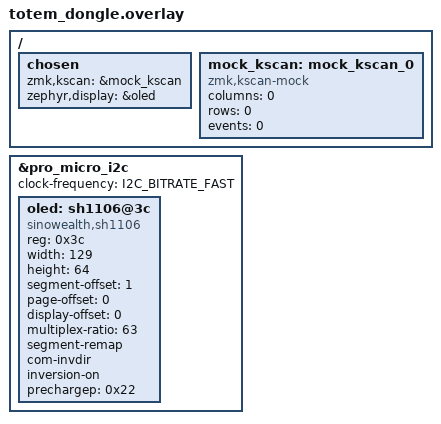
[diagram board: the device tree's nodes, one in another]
/* Import the logical layout and keymap for ZMK Studio */
#include <boards/shields/totem/totem.dtsi>

/ {
    chosen {
        zmk,kscan = &mock_kscan;
        zephyr,display = &oled;
    };

    /* Provide a dummy scanner so the nice!nano doesn't panic looking for keys */
    mock_kscan: mock_kscan_0 {
        compatible = "zmk,kscan-mock";
        columns = <0>;
        rows = <0>;
        events = <0>;
    };
};

/* Use the native nice!nano pins for the I2C OLED */
&pro_micro_i2c {
    status = "okay";
    clock-frequency = <I2C_BITRATE_FAST>;

    oled: sh1106@3c {
        compatible = "sinowealth,sh1106";
        reg = <0x3c>;
        width = <129>;
        height = <64>;
        segment-offset = <1>;
        page-offset = <0>;
        display-offset = <0>;
        multiplex-ratio = <63>;
        segment-remap;
        com-invdir;
        inversion-on;
        prechargep = <0x22>;
    };
};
